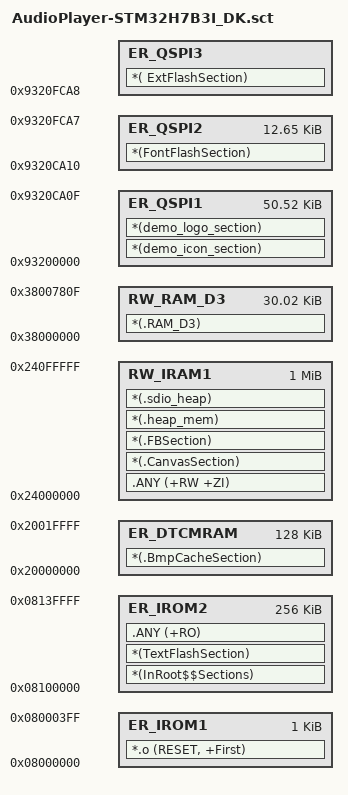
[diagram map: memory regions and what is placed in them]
; *************************************************************
; *** Scatter-Loading Description File generated by uVision ***
; *************************************************************


LR_IROM1 0x08000000  0x400{    ; load region size_region
  ER_IROM1 0x08000000   0x400 {  ; load address = execution address
   *.o (RESET, +First)
     }
  }

LR_IROM2 0x08100000  0x40000     {    ; load region size_region
  ER_IROM2 0x08100000 0x40000   {  ; load address = execution address
   *(InRoot$$Sections)
   *(TextFlashSection)
     .ANY (+RO)
     }
   ER_DTCMRAM 0x20000000 0x20000  {     ; RW data
	    *(.BmpCacheSection)
     }	
	 
  RW_IRAM1 0x24000000 0x100000  {  ; RW data
    .ANY (+RW +ZI)
	*(.CanvasSection)
	*(.FBSection)
    *(.heap_mem) 
    *(.sdio_heap) 	
  }

   RW_RAM_D3 0x38000000 0x7810    { ; RW data
        *(.RAM_D3)
    } 
  }
    
 LR_QSPI 0x93200000  0x400000{    ; load region size_region
  ER_QSPI1 0x93200000 0xca10    {
     *(demo_icon_section)    
     *(demo_logo_section) 
	 }	
  ER_QSPI2 0x9320ca10 0x3298    {
     *(FontFlashSection)
	 }	 	 
  ER_QSPI3 0x9320fca8     {
     *( ExtFlashSection)
	 }	 
	 }	      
